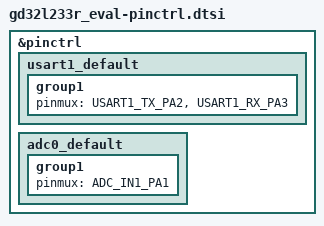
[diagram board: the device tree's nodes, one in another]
/*
 * Copyright (c) 2022 BrainCo Inc.
 * SPDX-License-Identifier: Apache-2.0
 */

#include <dt-bindings/pinctrl/gd32l233r(b-c)xx-pinctrl.h>

&pinctrl {
	usart1_default: usart1_default {
		group1 {
			pinmux = <USART1_TX_PA2>, <USART1_RX_PA3>;
		};
	};

	adc0_default: adc0_default {
		group1 {
			pinmux = <ADC_IN1_PA1>;
		};
	};
};
